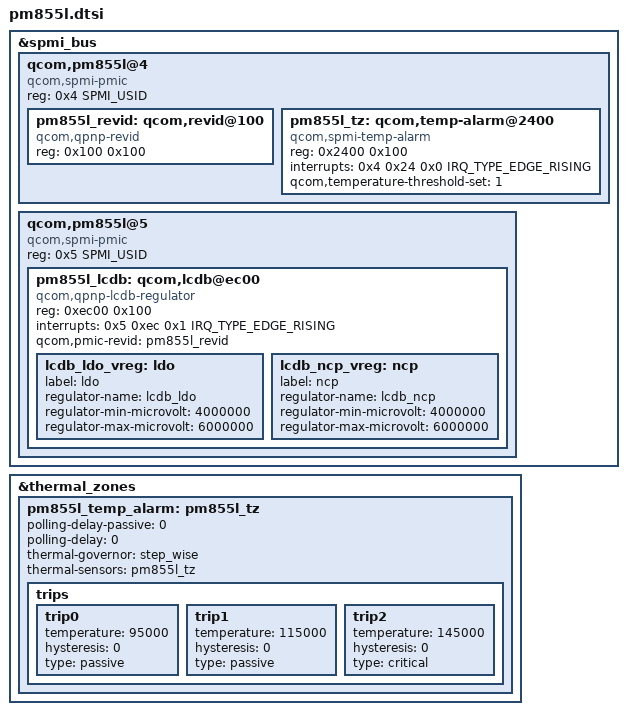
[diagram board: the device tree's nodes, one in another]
/*
 * Copyright (c) 2017-2018, The Linux Foundation. All rights reserved.
 *
 * This program is free software; you can redistribute it and/or modify
 * it under the terms of the GNU General Public License version 2 and
 * only version 2 as published by the Free Software Foundation.
 *
 * This program is distributed in the hope that it will be useful,
 * but WITHOUT ANY WARRANTY; without even the implied warranty of
 * MERCHANTABILITY or FITNESS FOR A PARTICULAR PURPOSE.  See the
 * GNU General Public License for more details.
 */

#include <dt-bindings/spmi/spmi.h>
#include <dt-bindings/interrupt-controller/irq.h>

&spmi_bus {
	qcom,pm855l@4 {
		compatible = "qcom,spmi-pmic";
		reg = <0x4 SPMI_USID>;
		#address-cells = <2>;
		#size-cells = <0>;

		pm855l_revid: qcom,revid@100 {
			compatible = "qcom,qpnp-revid";
			reg = <0x100 0x100>;
		};

		pm855l_tz: qcom,temp-alarm@2400 {
			compatible = "qcom,spmi-temp-alarm";
			reg = <0x2400 0x100>;
			interrupts = <0x4 0x24 0x0 IRQ_TYPE_EDGE_RISING>;
			#thermal-sensor-cells = <0>;
			qcom,temperature-threshold-set = <1>;
		};
	};

	qcom,pm855l@5 {
		compatible ="qcom,spmi-pmic";
		reg = <0x5 SPMI_USID>;
		#address-cells = <2>;
		#size-cells = <0>;

		pm855l_lcdb: qcom,lcdb@ec00 {
			compatible = "qcom,qpnp-lcdb-regulator";
			#address-cells = <1>;
			#size-cells = <1>;
			reg = <0xec00 0x100>;
			interrupts = <0x5 0xec 0x1 IRQ_TYPE_EDGE_RISING>;
			interrupt-names = "sc-irq";

			qcom,pmic-revid = <&pm855l_revid>;

			lcdb_ldo_vreg: ldo {
				label = "ldo";
				regulator-name = "lcdb_ldo";
				regulator-min-microvolt = <4000000>;
				regulator-max-microvolt = <6000000>;
			};

			lcdb_ncp_vreg: ncp {
				label = "ncp";
				regulator-name = "lcdb_ncp";
				regulator-min-microvolt = <4000000>;
				regulator-max-microvolt = <6000000>;
			};
		};
	};
};

&thermal_zones {
	pm855l_temp_alarm: pm855l_tz {
		polling-delay-passive = <0>;
		polling-delay = <0>;
		thermal-governor = "step_wise";
		thermal-sensors = <&pm855l_tz>;

		trips {
			trip0 {
				temperature = <95000>;
				hysteresis = <0>;
				type = "passive";
			};
			trip1 {
				temperature = <115000>;
				hysteresis = <0>;
				type = "passive";
			};
			trip2 {
				temperature = <145000>;
				hysteresis = <0>;
				type = "critical";
			};
		};
	};
};
